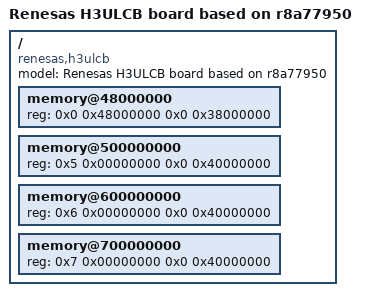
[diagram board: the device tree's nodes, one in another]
// SPDX-License-Identifier: GPL-2.0
/*
 * Device Tree Source for the H3ULCB (R-Car Starter Kit Premier) board with R-Car H3 ES1.x
 *
 * Copyright (C) 2016 Renesas Electronics Corp.
 * Copyright (C) 2016 Cogent Embedded, Inc.
 */

/dts-v1/;
#include "r8a77950.dtsi"
#include "ulcb.dtsi"

/ {
	model = "Renesas H3ULCB board based on r8a77950";
	compatible = "renesas,h3ulcb", "renesas,r8a7795";

	memory@48000000 {
		device_type = "memory";
		/* first 128MB is reserved for secure area. */
		reg = <0x0 0x48000000 0x0 0x38000000>;
	};

	memory@500000000 {
		device_type = "memory";
		reg = <0x5 0x00000000 0x0 0x40000000>;
	};

	memory@600000000 {
		device_type = "memory";
		reg = <0x6 0x00000000 0x0 0x40000000>;
	};

	memory@700000000 {
		device_type = "memory";
		reg = <0x7 0x00000000 0x0 0x40000000>;
	};
};
